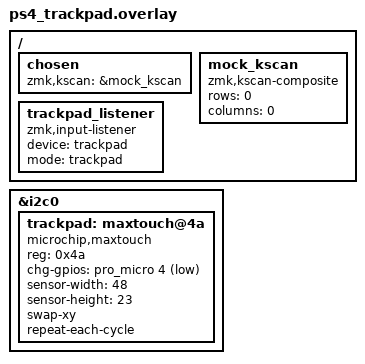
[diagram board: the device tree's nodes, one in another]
/*
 * Copyright (c) 2024 The ZMK Contributors
 *
 * SPDX-License-Identifier: MIT
 */

&i2c0 {
	status = "okay";
	trackpad: maxtouch@4a {
		compatible = "microchip,maxtouch";
		reg = <0x4a>;
		chg-gpios = <&pro_micro 4 (GPIO_ACTIVE_LOW | GPIO_PULL_UP)>;
		sensor-width = <48>;
		sensor-height= <23>;
		swap-xy;
		repeat-each-cycle;
	};
};

/ {
	chosen {
		zmk,kscan = &mock_kscan;
	};

	mock_kscan: mock_kscan {
		compatible = "zmk,kscan-composite";
		rows = <0>;
		columns = <0>;
	};

	/*
	 * This node is required for ZMK to listen to the trackpad
	 * for pointer movement and gestures.
	 */
	trackpad_listener {
		compatible = "zmk,input-listener";
		device = <&trackpad>;
		mode = "trackpad";
	};
};
